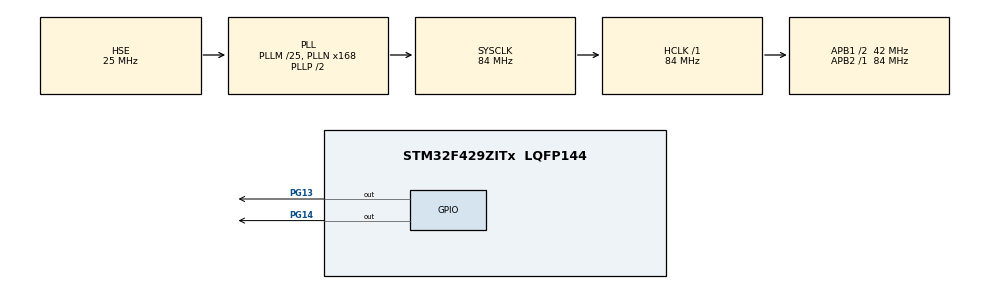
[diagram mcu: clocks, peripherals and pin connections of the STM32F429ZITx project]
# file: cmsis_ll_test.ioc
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FREERTOS.Tasks01=defaultTask,24,128,StartDefaultTask,Default,NULL
Mcu.Family=STM32F4
Mcu.Name=STM32F429ZITx
Mcu.Package=LQFP144
NVIC.PriorityGroup=NVIC_PRIORITYGROUP_4
NVIC.TIM1_UP_TIM10_IRQn=true\:0\:0\:false\:false\:true\:false\:false\:true
NVIC.TimeBase=TIM1_UP_TIM10_IRQn
NVIC.TimeBaseIP=TIM1
PA13.Mode=Serial_Wire
PA13.Signal=SYS_JTMS-SWDIO
PA14.Mode=Serial_Wire
PA14.Signal=SYS_JTCK-SWCLK
PG13.Signal=GPIO_Output
PG14.Signal=GPIO_Output
PH0/OSC_IN.Mode=HSE-External-Oscillator
PH0/OSC_IN.Signal=RCC_OSC_IN
PH1/OSC_OUT.Mode=HSE-External-Oscillator
PH1/OSC_OUT.Signal=RCC_OSC_OUT
ProjectManager.HeapSize=0x200
ProjectManager.StackSize=0x400
ProjectManager.TargetToolchain=MDK-ARM V5
RCC.48MHZClocksFreq_Value=42000000
RCC.AHBFreq_Value=84000000
RCC.APB1CLKDivider=RCC_HCLK_DIV2
RCC.APB1Freq_Value=42000000
RCC.APB1TimFreq_Value=84000000
RCC.APB2Freq_Value=84000000
RCC.APB2TimFreq_Value=84000000
RCC.CortexFreq_Value=84000000
RCC.HCLKFreq_Value=84000000
RCC.HSE_VALUE=25000000
RCC.HSI_VALUE=16000000
RCC.LSE_VALUE=32768
RCC.PLLM=25
RCC.PLLN=168
RCC.PLLSourceVirtual=RCC_PLLSOURCE_HSE
RCC.SYSCLKFreq_VALUE=84000000
RCC.SYSCLKSource=RCC_SYSCLKSOURCE_PLLCLK
RCC.VCOOutputFreq_Value=168000000
VP_FREERTOS_VS_CMSIS_V2.Mode=CMSIS_V2
VP_SYS_VS_tim1.Mode=TIM1
board=custom

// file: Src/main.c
/* USER CODE BEGIN Header */
/**
  ******************************************************************************
  * @file           : main.c
  * @brief          : Main program body
  ******************************************************************************
  * @attention
  *
  * <h2><center>&copy; Copyright (c) 2020 STMicroelectronics.
  * All rights reserved.</center></h2>
  *
  * This software component is licensed by ST under Ultimate Liberty license
  * SLA0044, the "License"; You may not use this file except in compliance with
  * the License. You may obtain a copy of the License at:
  *                             www.st.com/SLA0044
  *
  ******************************************************************************
  */
/* USER CODE END Header */

#include "main.h"
#include "cmsis_os.h"

/* USER CODE BEGIN Includes */
#include "task.h"
/* USER CODE END Includes */

osThreadId_t defaultTaskHandle;

void SystemClock_Config(void);
static void MX_GPIO_Init(void);
void StartDefaultTask(void *argument);

/* USER CODE BEGIN PFP */
void vTaskLed1 (void *argument);
/* USER CODE END PFP */

int main(void)
{

  /* MCU Configuration--------------------------------------------------------*/

  /* Reset of all peripherals, Initializes the Flash interface and the Systick. */
  HAL_Init();

  /* Configure the system clock */
  SystemClock_Config();

  /* Initialize all configured peripherals */
  MX_GPIO_Init();

  osKernelInitialize();

  /* Create the thread(s) */
  /* definition and creation of defaultTask */
  const osThreadAttr_t defaultTask_attributes = {
    .name = "defaultTask",
    .priority = (osPriority_t) osPriorityNormal,
    .stack_size = 128
  };
  defaultTaskHandle = osThreadNew(StartDefaultTask, NULL, &defaultTask_attributes);

  /* Start scheduler */
  osKernelStart();

  /* We should never get here as control is now taken by the scheduler */

  /* Infinite loop */
  /* USER CODE BEGIN WHILE */

	//	xTaskCreate(vTaskLed1, "LED", 100, NULL, 1, NULL );

	//	vTaskStartScheduler();
  while (1)
  {
    /* USER CODE END WHILE */

    /* USER CODE BEGIN 3 */
		HAL_GPIO_WritePin(GPIOG, GPIO_PIN_13,GPIO_PIN_SET);
		HAL_GPIO_WritePin(GPIOG, GPIO_PIN_14,GPIO_PIN_SET);
  }
  /* USER CODE END 3 */
}

void SystemClock_Config(void)
{
  RCC_OscInitTypeDef RCC_OscInitStruct = {0};
  RCC_ClkInitTypeDef RCC_ClkInitStruct = {0};

  /** Configure the main internal regulator output voltage
  */
  __HAL_RCC_PWR_CLK_ENABLE();
  __HAL_PWR_VOLTAGESCALING_CONFIG(PWR_REGULATOR_VOLTAGE_SCALE3);
  /** Initializes the CPU, AHB and APB busses clocks
  */
  RCC_OscInitStruct.OscillatorType = RCC_OSCILLATORTYPE_HSE;
  RCC_OscInitStruct.HSEState = RCC_HSE_ON;
  RCC_OscInitStruct.PLL.PLLState = RCC_PLL_ON;
  RCC_OscInitStruct.PLL.PLLSource = RCC_PLLSOURCE_HSE;
  RCC_OscInitStruct.PLL.PLLM = 25;
  RCC_OscInitStruct.PLL.PLLN = 168;
  RCC_OscInitStruct.PLL.PLLP = RCC_PLLP_DIV2;
  RCC_OscInitStruct.PLL.PLLQ = 4;
  if (HAL_RCC_OscConfig(&RCC_OscInitStruct) != HAL_OK)
  {
    Error_Handler();
  }
  /** Initializes the CPU, AHB and APB busses clocks
  */
  RCC_ClkInitStruct.ClockType = RCC_CLOCKTYPE_HCLK|RCC_CLOCKTYPE_SYSCLK
                              |RCC_CLOCKTYPE_PCLK1|RCC_CLOCKTYPE_PCLK2;
  RCC_ClkInitStruct.SYSCLKSource = RCC_SYSCLKSOURCE_PLLCLK;
  RCC_ClkInitStruct.AHBCLKDivider = RCC_SYSCLK_DIV1;
  RCC_ClkInitStruct.APB1CLKDivider = RCC_HCLK_DIV2;
  RCC_ClkInitStruct.APB2CLKDivider = RCC_HCLK_DIV1;

  if (HAL_RCC_ClockConfig(&RCC_ClkInitStruct, FLASH_LATENCY_2) != HAL_OK)
  {
    Error_Handler();
  }
}

static void MX_GPIO_Init(void)
{
  GPIO_InitTypeDef GPIO_InitStruct = {0};

  /* GPIO Ports Clock Enable */
  __HAL_RCC_GPIOH_CLK_ENABLE();
  __HAL_RCC_GPIOA_CLK_ENABLE();
  __HAL_RCC_GPIOG_CLK_ENABLE();

  /*Configure GPIO pin Output Level */
  HAL_GPIO_WritePin(GPIOG, GPIO_PIN_13|GPIO_PIN_14, GPIO_PIN_RESET);

  /*Configure GPIO pins : PG13 PG14 */
  GPIO_InitStruct.Pin = GPIO_PIN_13|GPIO_PIN_14;
  GPIO_InitStruct.Mode = GPIO_MODE_OUTPUT_PP;
  GPIO_InitStruct.Pull = GPIO_NOPULL;
  GPIO_InitStruct.Speed = GPIO_SPEED_FREQ_LOW;
  HAL_GPIO_Init(GPIOG, &GPIO_InitStruct);

}

/* USER CODE BEGIN 4 */
void vTaskLed1 (void *argument)
{
	while(1)
	{
			GPIOG-> ODR |= GPIO_ODR_OD13_Msk;
			GPIOG-> ODR &= ~GPIO_ODR_OD14;
			vTaskDelay(1000);
			GPIOG-> ODR |= GPIO_ODR_OD14_Msk;
			GPIOG-> ODR &= ~GPIO_ODR_OD13;
			vTaskDelay(1000);
	}
}

/* USER CODE END 4 */

void StartDefaultTask(void *argument)
{

  for(;;)
  {
    osDelay(1);
  }
}

void HAL_TIM_PeriodElapsedCallback(TIM_HandleTypeDef *htim)
{
  if (htim->Instance == TIM1) {
    HAL_IncTick();
  }
}

void Error_Handler(void)
{
}

/************************ (C) COPYRIGHT STMicroelectronics *****END OF FILE****/
